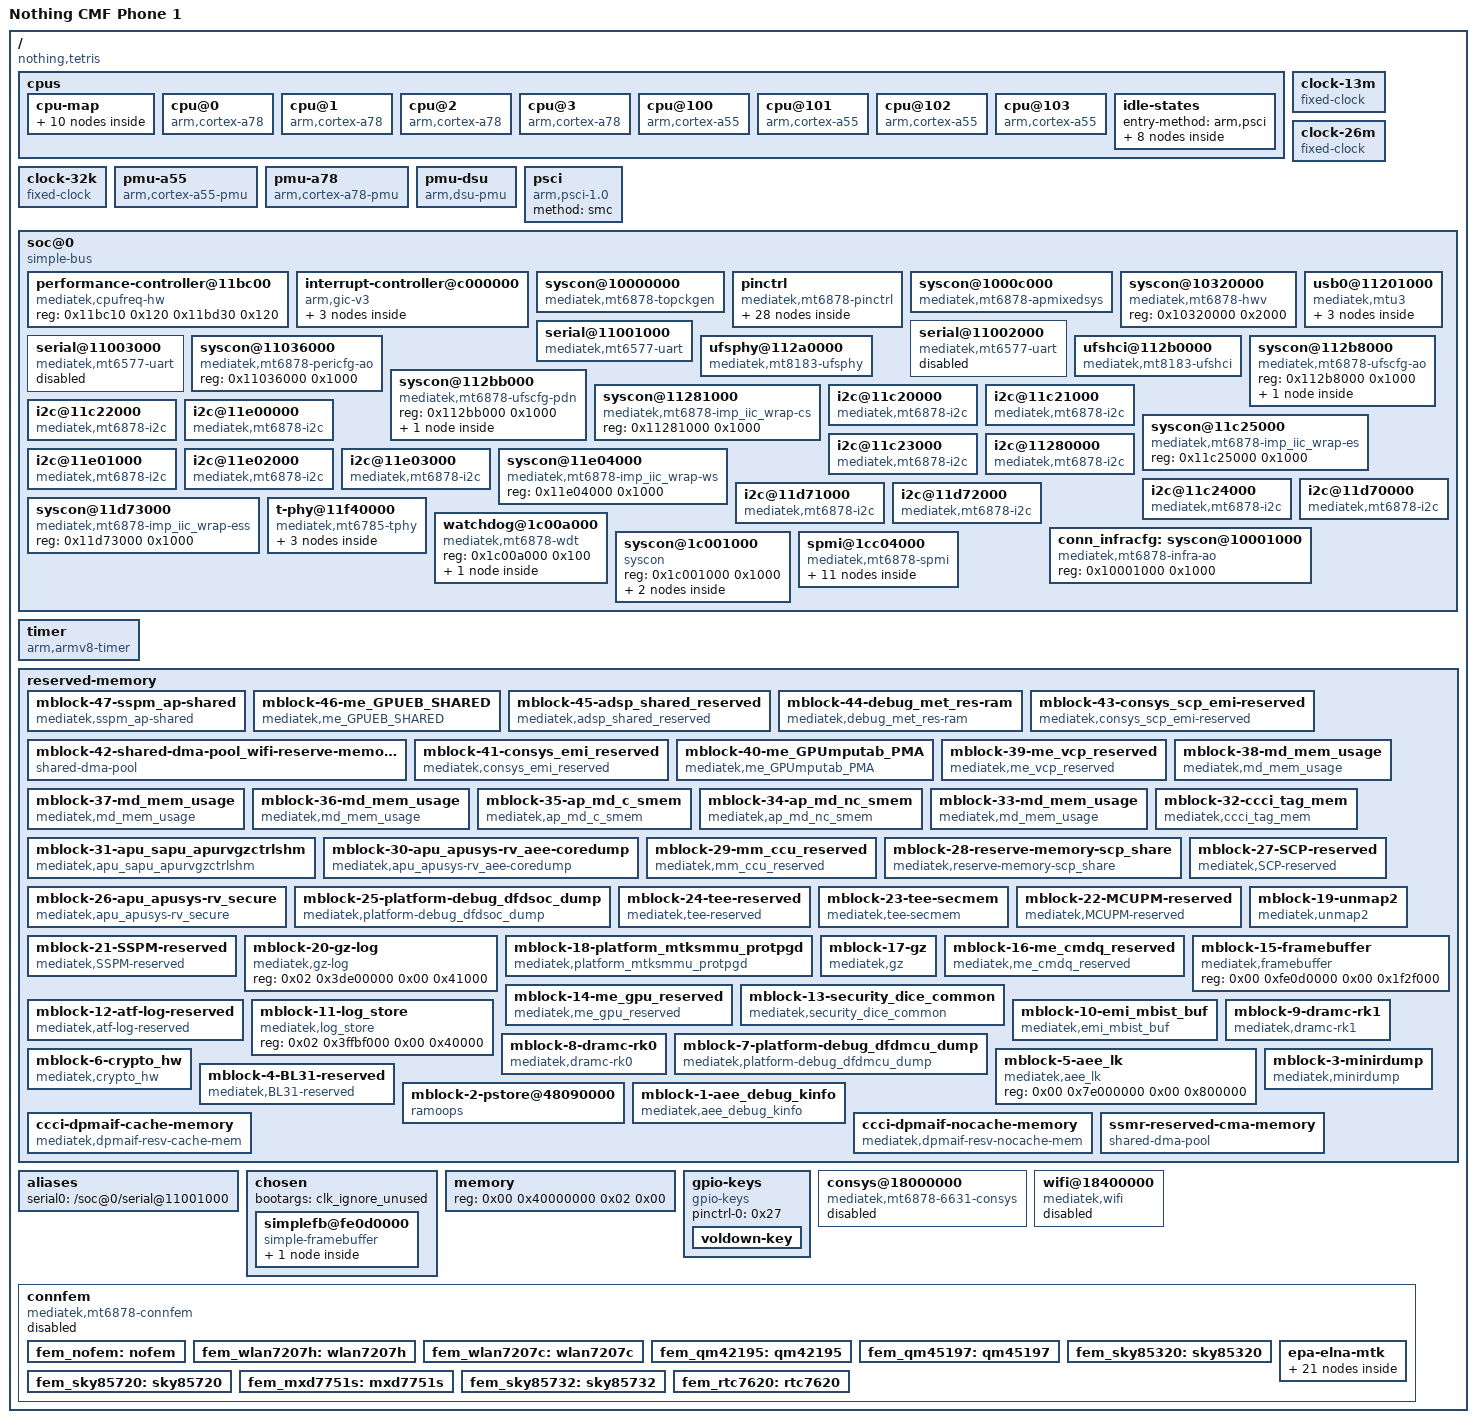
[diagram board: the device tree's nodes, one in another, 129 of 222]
/dts-v1/;

/ {
	compatible = "nothing,tetris", "mediatek,mt6878";
	#address-cells = <0x02>;
	#size-cells = <0x02>;
	interrupt-parent = <0x01>;
	model = "Nothing CMF Phone 1";
	chassis-type = "handset";

	cpus {
		#address-cells = <0x01>;
		#size-cells = <0x00>;

		cpu-map {

			cluster0 {

				core0 {
					cpu = <0x02>;
				};

				core1 {
					cpu = <0x03>;
				};

				core2 {
					cpu = <0x04>;
				};

				core3 {
					cpu = <0x05>;
				};
			};

			cluster1 {

				core0 {
					cpu = <0x06>;
				};

				core1 {
					cpu = <0x07>;
				};

				core2 {
					cpu = <0x08>;
				};

				core3 {
					cpu = <0x09>;
				};
			};
		};

		cpu@0 {
			device_type = "cpu";
			compatible = "arm,cortex-a78";
			reg = <0x00>;
			performance-domains = <0x0a 0x00>;
			enable-method = "psci";
			cpu-idle-states = <0x0b 0x0c 0x0d 0x0e 0x0f>;
			capacity-dmips-mhz = <0x10b>;
			phandle = <0x02>;
		};

		cpu@1 {
			device_type = "cpu";
			compatible = "arm,cortex-a78";
			reg = <0x100>;
			performance-domains = <0x0a 0x00>;
			enable-method = "psci";
			cpu-idle-states = <0x0b 0x0c 0x0d 0x0e 0x0f>;
			capacity-dmips-mhz = <0x10b>;
			phandle = <0x03>;
		};

		cpu@2 {
			device_type = "cpu";
			compatible = "arm,cortex-a78";
			reg = <0x200>;
			performance-domains = <0x0a 0x00>;
			enable-method = "psci";
			cpu-idle-states = <0x0b 0x0c 0x0d 0x0e 0x0f>;
			capacity-dmips-mhz = <0x10b>;
			phandle = <0x04>;
		};

		cpu@3 {
			device_type = "cpu";
			compatible = "arm,cortex-a78";
			reg = <0x300>;
			performance-domains = <0x0a 0x00>;
			enable-method = "psci";
			cpu-idle-states = <0x0b 0x0c 0x0d 0x0e 0x0f>;
			capacity-dmips-mhz = <0x10b>;
			phandle = <0x05>;
		};

		cpu@100 {
			device_type = "cpu";
			compatible = "arm,cortex-a55";
			reg = <0x400>;
			performance-domains = <0x0a 0x01>;
			enable-method = "psci";
			cpu-idle-states = <0x10 0x11 0x12 0x0e 0x0f>;
			capacity-dmips-mhz = <0x400>;
			phandle = <0x06>;
		};

		cpu@101 {
			device_type = "cpu";
			compatible = "arm,cortex-a55";
			reg = <0x500>;
			performance-domains = <0x0a 0x01>;
			enable-method = "psci";
			cpu-idle-states = <0x10 0x11 0x12 0x0e 0x0f>;
			capacity-dmips-mhz = <0x400>;
			phandle = <0x07>;
		};

		cpu@102 {
			device_type = "cpu";
			compatible = "arm,cortex-a55";
			reg = <0x600>;
			performance-domains = <0x0a 0x01>;
			enable-method = "psci";
			cpu-idle-states = <0x10 0x11 0x12 0x0e 0x0f>;
			capacity-dmips-mhz = <0x400>;
			phandle = <0x08>;
		};

		cpu@103 {
			device_type = "cpu";
			compatible = "arm,cortex-a55";
			reg = <0x700>;
			performance-domains = <0x0a 0x01>;
			enable-method = "psci";
			cpu-idle-states = <0x10 0x11 0x12 0x0e 0x0f>;
			capacity-dmips-mhz = <0x400>;
			phandle = <0x09>;
		};

		idle-states {
			entry-method = "arm,psci";

			cpuoff-l {
				compatible = "arm,idle-state";
				arm,psci-suspend-param = <0x10000>;
				local-timer-stop;
				entry-latency-us = <0x19>;
				exit-latency-us = <0x39>;
				min-residency-us = <0x1644>;
				phandle = <0x0b>;
			};

			cpuoff-b {
				compatible = "arm,idle-state";
				arm,psci-suspend-param = <0x10000>;
				local-timer-stop;
				entry-latency-us = <0x23>;
				exit-latency-us = <0x52>;
				min-residency-us = <0x762>;
				phandle = <0x10>;
			};

			clusteroff-l {
				compatible = "arm,idle-state";
				arm,psci-suspend-param = <0x1010001>;
				local-timer-stop;
				entry-latency-us = <0x39>;
				exit-latency-us = <0x86>;
				min-residency-us = <0x1644>;
				phandle = <0x0c>;
			};

			clusteroff-b {
				compatible = "arm,idle-state";
				arm,psci-suspend-param = <0x1010001>;
				local-timer-stop;
				entry-latency-us = <0x32>;
				exit-latency-us = <0x90>;
				min-residency-us = <0x99c>;
				phandle = <0x11>;
			};

			mcusysoff-l {
				compatible = "arm,idle-state";
				arm,psci-suspend-param = <0x2010007>;
				local-timer-stop;
				entry-latency-us = <0x35f>;
				exit-latency-us = <0x4d5>;
				min-residency-us = <0x1644>;
				phandle = <0x0d>;
			};

			mcusysoff-b {
				compatible = "arm,idle-state";
				arm,psci-suspend-param = <0x2010007>;
				local-timer-stop;
				entry-latency-us = <0x288>;
				exit-latency-us = <0x494>;
				min-residency-us = <0x11da>;
				phandle = <0x12>;
			};

			system-vcore {
				compatible = "arm,idle-state";
				arm,psci-suspend-param = <0x20100ff>;
				local-timer-stop;
				entry-latency-us = <0x960>;
				exit-latency-us = <0x12c0>;
				min-residency-us = <0x8980>;
				phandle = <0x0e>;
			};

			s2idle {
				compatible = "arm,idle-state";
				arm,psci-suspend-param = <0x20180ff>;
				local-timer-stop;
				entry-latency-us = <0x2710>;
				exit-latency-us = <0x2710>;
				min-residency-us = <0xffffffff>;
				phandle = <0x0f>;
			};
		};
	};

	clock-13m {
		compatible = "fixed-clock";
		#clock-cells = <0x00>;
		clock-frequency = <0xc65d40>;
		clock-output-names = "clk13m";
	};

	clock-26m {
		compatible = "fixed-clock";
		#clock-cells = <0x00>;
		clock-frequency = <0x18cba80>;
		clock-output-names = "clk26m";
		phandle = <0x17>;
	};

	clock-32k {
		compatible = "fixed-clock";
		#clock-cells = <0x00>;
		clock-frequency = <0x7d00>;
		clock-output-names = "clk32k";
	};

	pmu-a55 {
		compatible = "arm,cortex-a55-pmu";
		interrupt-parent = <0x01>;
		interrupts = <0x01 0x07 0x04 0x13>;
	};

	pmu-a78 {
		compatible = "arm,cortex-a78-pmu";
		interrupt-parent = <0x01>;
		interrupts = <0x01 0x07 0x04 0x14>;
	};

	pmu-dsu {
		compatible = "arm,dsu-pmu";
		cpus = <0x02 0x03 0x04 0x05 0x06 0x07 0x08 0x09>;
		interrupts = <0x00 0x23 0x04 0x00>;
	};

	psci {
		compatible = "arm,psci-1.0";
		method = "smc";
	};

	soc@0 {
		compatible = "simple-bus";
		ranges = <0x00 0x00 0x00 0x20000000>;
		#address-cells = <0x01>;
		#size-cells = <0x01>;

		performance-controller@11bc00 {
			compatible = "mediatek,cpufreq-hw";
			reg = <0x11bc10 0x120 0x11bd30 0x120>;
			#performance-domain-cells = <0x01>;
			phandle = <0x0a>;
		};

		interrupt-controller@c000000 {
			compatible = "arm,gic-v3";
			reg = <0xc000000 0x40000 0xc040000 0x200000>;
			#interrupt-cells = <0x04>;
			interrupt-controller;
			interrupts = <0x01 0x09 0x04 0x00>;
			phandle = <0x01>;

			ppi-partitions {

				interrupt-partition-0 {
					affinity = <0x02 0x03 0x04 0x05>;
					phandle = <0x13>;
				};

				interrupt-partition-1 {
					affinity = <0x06 0x07 0x08 0x09>;
					phandle = <0x14>;
				};
			};
		};

		syscon@10000000 {
			compatible = "mediatek,mt6878-topckgen", "syscon";
			reg = <0x10000000 0x1000>;
			#clock-cells = <0x01>;
			hw-voter-regmap = <0x15>;
			phandle = <0x1a>;
		};

		pinctrl {
			compatible = "mediatek,mt6878-pinctrl";
			reg = <0x10005000 0x1000 0x11d10000 0x1000 0x11d30000 0x1000 0x11d40000 0x1000 0x11d50000 0x1000 0x11d60000 0x1000 0x11e20000 0x1000 0x11e30000 0x1000 0x11eb0000 0x1000 0x11ec0000 0x1000 0x11ce0000 0x1000 0x11de0000 0x1000 0x11e60000 0x1000 0x1c01e000 0x1000 0x11ce0000 0x1000 0x11de0000 0x1000 0x11e60000 0x1000 0x1c01e000 0x1000>;
			reg-names = "gpio", "iocfg_bl", "iocfg_bm", "iocfg_br", "iocfg_bl1", "iocfg_br1", "iocfg_lm", "iocfg_lt", "iocfg_rm", "iocfg_rt", "eint-e", "eint-s", "eint-w", "eint-c";
			gpio-controller;
			#gpio-cells = <0x02>;
			gpio-ranges = <0x16 0x00 0x00 0xc4>;
			interrupt-controller;
			#interrupt-cells = <0x02>;
			interrupts = <0x00 0xef 0x04 0x00>;
			phandle = <0x16>;

			key-default {
				phandle = <0x27>;

				pins-cmd1-dat {
					pinmux = <0x3600>;
					input-enable;
					bias-pull-up;
				};
			};
		};

		syscon@1000c000 {
			compatible = "mediatek,mt6878-apmixedsys", "syscon";
			reg = <0x1000c000 0x1000>;
			#clock-cells = <0x01>;
			mediatek,hardware-voter = <0x15>;
		};

		syscon@10320000 {
			compatible = "mediatek,mt6878-hwv", "syscon";
			reg = <0x10320000 0x2000>;
			phandle = <0x15>;
		};

		serial@11001000 {
			compatible = "mediatek,mt6577-uart";
			reg = <0x11001000 0x1000>;
			interrupts = <0x00 0x18d 0x04 0x00>;
			clocks = <0x17 0x18 0x00>;
			clock-names = "baud", "bus";
			status = "okay";
		};

		serial@11002000 {
			compatible = "mediatek,mt6577-uart";
			reg = <0x11002000 0x1000>;
			interrupts = <0x00 0x18e 0x04 0x00>;
			clocks = <0x17 0x18 0x01>;
			clock-names = "baud", "bus";
			status = "disabled";
		};

		serial@11003000 {
			compatible = "mediatek,mt6577-uart";
			reg = <0x11003000 0x1000>;
			interrupts = <0x00 0x18f 0x04 0x00>;
			clocks = <0x17 0x18 0x02>;
			clock-names = "baud", "bus";
			status = "disabled";
		};

		syscon@11036000 {
			compatible = "mediatek,mt6878-pericfg-ao", "syscon";
			reg = <0x11036000 0x1000>;
			#clock-cells = <0x01>;
			phandle = <0x18>;
		};

		usb0@11201000 {
			dr_mode = "peripheral";
			compatible = "mediatek,mtu3";
			reg = <0x11201000 0x2e00 0x11203e00 0x100>;
			reg-names = "mac", "ippc";
			interrupts = <0x00 0x180 0x04 0x00>;
			phy-cells = <0x01>;
			phys = <0x19 0x03>;
			clocks = <0x1a 0x1f 0x1a 0x20 0x18 0x12>;
			clock-names = "sys_ck", "host_ck", "frmcnt_ck";
			#address-cells = <0x01>;
			#size-cells = <0x01>;
			ranges;
			mediatek,syscon-wakeup = <0x18 0x214 0x69>;
			wakeup-source;

			xhci0@11200000 {
				compatible = "mediatek,mtk-xhci";
				reg = <0x11200000 0x1000>;
				reg-names = "mac";
				interrupts = <0x00 0x181 0x04 0x00>;
				clocks = <0x17>;
				clock-names = "sys_ck";

				port {

					endpoint {
						remote-endpoint = <0x1b>;
						phandle = <0x25>;
					};
				};
			};
		};

		ufsphy@112a0000 {
			compatible = "mediatek,mt8183-ufsphy";
			#phy-cells = <0x00>;
			clocks = <0x17 0x17>;
			clock-names = "unipro", "mp";
			reg = <0x112a0000 0x10000>;
			status = "okay";
			phandle = <0x1c>;
		};

		ufshci@112b0000 {
			compatible = "mediatek,mt8183-ufshci";
			reg = <0x112b0000 0x2300>;
			phys = <0x1c>;
			interrupts = <0x00 0x189 0x04 0x00>;
			clocks = <0x1a 0x29 0x1a 0x28 0x1a 0x2a 0x1d 0x00 0x1d 0x01 0x1d 0x02 0x1d 0x03 0x1d 0x04 0x1d 0x05 0x1e 0x00 0x1e 0x01 0x1e 0x02 0x1e 0x03>;
			clock-names = "ufs_sel", "ufs_fde", "ufs_mbist", "unipro_tx_sym", "unipro_rx_sym0", "unipro_rx_sym1", "unipro_sys", "unipro_phy_sap", "phy_top_ahb_s_bus", "ufshci_ufs", "ufshci_aes", "ufshci_ufs_ahb", "ufshci_aes_axi";
			freq-table-hz = <0x00 0x00 0x00 0x00 0x00 0x00 0x00 0x00 0x00 0x00 0x00 0x00 0x00 0x00 0x00 0x00 0x00 0x00 0x00 0x00 0x00 0x00 0x00 0x00 0x00 0x00>;
			resets = <0x1f 0x00 0x1f 0x01 0x1f 0x02>;
			reset-names = "unipro_rst", "crypto_rst", "hci_rst";
			mediatek,ufs-disable-mcq;
			status = "okay";
		};

		syscon@112b8000 {
			compatible = "mediatek,mt6878-ufscfg-ao", "syscon", "simple-mfd";
			reg = <0x112b8000 0x1000>;
			#clock-cells = <0x01>;
			phandle = <0x1d>;

			reset-controller {
				compatible = "ti,syscon-reset";
				#reset-cells = <0x01>;
				ti,reset-bits = <0x48 0x08 0x4c 0x08 0x00 0x00 0x1c>;
			};
		};

		syscon@112bb000 {
			compatible = "mediatek,mt6878-ufscfg-pdn", "syscon", "simple-mfd";
			reg = <0x112bb000 0x1000>;
			#clock-cells = <0x01>;
			phandle = <0x1e>;

			reset-controller {
				compatible = "ti,syscon-reset";
				#reset-cells = <0x01>;
				ti,reset-bits = <0x48 0x00 0x4c 0x00 0x00 0x00 0x1c 0x48 0x01 0x4c 0x01 0x00 0x00 0x1c 0x48 0x02 0x4c 0x02 0x00 0x00 0x1c>;
				phandle = <0x1f>;
			};
		};

		syscon@11281000 {
			compatible = "mediatek,mt6878-imp_iic_wrap-cs", "syscon";
			reg = <0x11281000 0x1000>;
			#clock-cells = <0x01>;
			phandle = <0x23>;
		};

		i2c@11c20000 {
			compatible = "mediatek,mt6878-i2c", "mediatek,mt8188-i2c";
			reg = <0x11c20000 0x1000 0x11300200 0x80>;
			interrupts = <0x00 0x190 0x04 0x00>;
			clocks = <0x21 0x00 0x18 0x11>;
			clock-names = "main", "dma";
			clock-div = <0x01>;
		};

		i2c@11c21000 {
			compatible = "mediatek,mt6878-i2c", "mediatek,mt8188-i2c";
			reg = <0x11c21000 0x1000 0x11300280 0x80>;
			interrupts = <0x00 0x191 0x04 0x00>;
			clocks = <0x21 0x01 0x18 0x11>;
			clock-names = "main", "dma";
			clock-div = <0x01>;
		};

		i2c@11c22000 {
			compatible = "mediatek,mt6878-i2c", "mediatek,mt8188-i2c";
			reg = <0x11c22000 0x1000 0x11300300 0x100>;
			interrupts = <0x00 0x192 0x04 0x00>;
			clocks = <0x21 0x02 0x18 0x11>;
			clock-names = "main", "dma";
			clock-div = <0x01>;
		};

		syscon@11c25000 {
			compatible = "mediatek,mt6878-imp_iic_wrap-es", "syscon";
			reg = <0x11c25000 0x1000>;
			#clock-cells = <0x01>;
			phandle = <0x21>;
		};

		i2c@11e00000 {
			compatible = "mediatek,mt6878-i2c", "mediatek,mt8188-i2c";
			reg = <0x11e00000 0x1000 0x11300400 0x80>;
			interrupts = <0x00 0x193 0x04 0x00>;
			clocks = <0x22 0x00 0x18 0x11>;
			clock-names = "main", "dma";
			clock-div = <0x01>;
		};

		i2c@11c23000 {
			compatible = "mediatek,mt6878-i2c", "mediatek,mt8188-i2c";
			reg = <0x11c23000 0x1000 0x11300480 0x100>;
			interrupts = <0x00 0x194 0x04 0x00>;
			clocks = <0x21 0x03 0x18 0x11>;
			clock-names = "main", "dma";
			clock-div = <0x01>;
		};

		i2c@11280000 {
			compatible = "mediatek,mt6878-i2c", "mediatek,mt8188-i2c";
			#address-cells = <0x01>;
			#size-cells = <0x00>;
			reg = <0x11280000 0x1000 0x11300580 0x80>;
			interrupts = <0x00 0x195 0x04 0x00>;
			clocks = <0x23 0x00 0x18 0x11>;
			clock-names = "main", "dma";
			clock-div = <0x01>;
		};

		i2c@11e01000 {
			compatible = "mediatek,mt6878-i2c", "mediatek,mt8188-i2c";
			#address-cells = <0x01>;
			#size-cells = <0x00>;
			reg = <0x11e01000 0x1000 0x11300600 0x80>;
			interrupts = <0x00 0x196 0x04 0x00>;
			clocks = <0x22 0x01 0x18 0x11>;
			clock-names = "main", "dma";
			clock-div = <0x01>;
		};

		i2c@11e02000 {
			compatible = "mediatek,mt6878-i2c", "mediatek,mt8188-i2c";
			reg = <0x11e02000 0x1000 0x11300680 0x100>;
			interrupts = <0x00 0x197 0x04 0x00>;
			clocks = <0x22 0x02 0x18 0x11>;
			clock-names = "main", "dma";
			clock-div = <0x01>;
			scl-gpio-id = <0x8b>;
			sda-gpio-id = <0x8c>;
		};

		i2c@11e03000 {
			compatible = "mediatek,mt6878-i2c", "mediatek,mt8188-i2c";
			reg = <0x11e03000 0x1000 0x11300780 0x100>;
			interrupts = <0x00 0x198 0x04 0x00>;
			clocks = <0x22 0x03 0x18 0x11>;
			clock-names = "main", "dma";
			clock-div = <0x01>;
		};

		syscon@11e04000 {
			compatible = "mediatek,mt6878-imp_iic_wrap-ws", "syscon";
			reg = <0x11e04000 0x1000>;
			#clock-cells = <0x01>;
			phandle = <0x22>;
		};

		i2c@11c24000 {
			compatible = "mediatek,mt6878-i2c", "mediatek,mt8188-i2c";
			reg = <0x11c24000 0x1000 0x11300880 0x100>;
			interrupts = <0x00 0x199 0x04 0x00>;
			clocks = <0x21 0x04 0x18 0x11>;
			clock-names = "main", "dma";
			clock-div = <0x01>;
		};

		i2c@11d70000 {
			compatible = "mediatek,mt6878-i2c", "mediatek,mt8188-i2c";
			reg = <0x11d70000 0x1000 0x11300980 0x80>;
			interrupts = <0x00 0x19a 0x04 0x00>;
			clocks = <0x24 0x00 0x18 0x11>;
			clock-names = "main", "dma";
			clock-div = <0x01>;
		};

		i2c@11d71000 {
			compatible = "mediatek,mt6878-i2c", "mediatek,mt8188-i2c";
			reg = <0x11d71000 0x1000 0x11300a00 0x80>;
			interrupts = <0x00 0x19b 0x04 0x00>;
			clocks = <0x24 0x01 0x18 0x11>;
			clock-names = "main", "dma";
			clock-div = <0x01>;
		};

		i2c@11d72000 {
			compatible = "mediatek,mt6878-i2c", "mediatek,mt8188-i2c";
			reg = <0x11d72000 0x1000 0x11300a80 0x80>;
			interrupts = <0x00 0x19c 0x04 0x00>;
			clocks = <0x24 0x02 0x18 0x11>;
			clock-names = "main", "dma";
			clock-div = <0x01>;
		};

		syscon@11d73000 {
			compatible = "mediatek,mt6878-imp_iic_wrap-ess", "syscon";
			reg = <0x11d73000 0x1000>;
			#clock-cells = <0x01>;
			phandle = <0x24>;
		};

		t-phy@11f40000 {
			compatible = "mediatek,mt6785-tphy", "mediatek,generic-tphy-v2";
			#address-cells = <0x01>;
			#size-cells = <0x01>;
			ranges = <0x00 0x11f40000 0x1000>;
			status = "okay";

			usb-phy@0 {
				reg = <0x00 0x700>;
				clocks = <0x17>;
				clock-names = "ref";
				#phy-cells = <0x01>;
				mediatek,software-role-switch;
				status = "okay";
				phandle = <0x19>;

				port {

					endpoint {
						remote-endpoint = <0x25>;
						phandle = <0x1b>;
					};
				};
			};
		};

		watchdog@1c00a000 {
			compatible = "mediatek,mt6878-wdt", "mediatek,mt6589-wdt", "syscon";
			reg = <0x1c00a000 0x100>;

			reboot-mode {
				compatible = "syscon-reboot-mode";
				offset = <0x24>;
				mask = <0x0f>;
				mode-charger = <0x01>;
				mode-recovery = <0x02>;
				mode-bootloader = <0x03>;
				mode-dm-verity-dev-corrupt = <0x04>;
				mode-kpoc = <0x05>;
				mode-ddr-reserve = <0x06>;
				mode-meta = <0x07>;
				mode-rpmbpk = <0x08>;
			};
		};
	};

	timer {
		compatible = "arm,armv8-timer";
		interrupt-parent = <0x01>;
		interrupts = <0x01 0x0d 0x08 0x00 0x01 0x0e 0x08 0x00 0x01 0x0b 0x08 0x00 0x01 0x0a 0x08 0x00>;
	};

	reserved-memory {
		#address-cells = <0x02>;
		#size-cells = <0x02>;
		ranges;

		mblock-47-sspm_ap-shared {
			reg = <0x00 0x7f970000 0x00 0x110000>;
			no-map;
			compatible = "mediatek,sspm_ap-shared";
		};

		mblock-46-me_GPUEB_SHARED {
			reg = <0x00 0x7fe70000 0x00 0x180000>;
			no-map;
			compatible = "mediatek,me_GPUEB_SHARED";
		};

		mblock-45-adsp_shared_reserved {
			reg = <0x00 0x9e000000 0x00 0xb70000>;
			no-map;
			compatible = "mediatek,adsp_shared_reserved";
		};

		mblock-44-debug_met_res-ram {
			reg = <0x00 0x9f3ff000 0x00 0xc00000>;
			no-map;
			compatible = "mediatek,debug_met_res-ram";
		};

		mblock-43-consys_scp_emi-reserved {
			reg = <0x00 0x87f00000 0x00 0x20000>;
			no-map;
			compatible = "mediatek,consys_scp_emi-reserved";
		};

		mblock-42-shared-dma-pool_wifi-reserve-memory_dma {
			phandle = <0x312>;
			reg = <0x00 0x86b00000 0x00 0x1400000>;
			no-map;
			compatible = "shared-dma-pool";
		};

		mblock-41-consys_emi_reserved {
			reg = <0x00 0x85e00000 0x00 0xd00000>;
			no-map;
			compatible = "mediatek,consys_emi_reserved";
		};

		mblock-40-me_GPUmputab_PMA {
			reg = <0x00 0x7e800000 0x00 0x600000>;
			no-map;
			compatible = "mediatek,me_GPUmputab_PMA";
		};

		mblock-39-me_vcp_reserved {
			reg = <0x00 0xbf500000 0x00 0x800000>;
			no-map;
			compatible = "mediatek,me_vcp_reserved";
		};

		mblock-38-md_mem_usage {
			reg = <0x00 0xed780000 0x00 0x880000>;
			no-map;
			compatible = "mediatek,md_mem_usage";
		};

		mblock-37-md_mem_usage {
			reg = <0x00 0xd4000000 0x00 0x6fa0000>;
			no-map;
			compatible = "mediatek,md_mem_usage";
		};

		mblock-36-md_mem_usage {
			reg = <0x00 0xd3500000 0x00 0x250000>;
			no-map;
			compatible = "mediatek,md_mem_usage";
		};

		mblock-35-ap_md_c_smem {
			reg = <0x00 0x88000000 0x00 0x2560000>;
			no-map;
			compatible = "mediatek,ap_md_c_smem";
		};

		mblock-34-ap_md_nc_smem {
			reg = <0x00 0x8c000000 0x00 0x130000>;
			no-map;
			compatible = "mediatek,ap_md_nc_smem";
		};

		mblock-33-md_mem_usage {
			reg = <0x00 0xd0000000 0x00 0x34e0000>;
			no-map;
			compatible = "mediatek,md_mem_usage";
		};

		mblock-32-ccci_tag_mem {
			reg = <0x00 0xbfdf0000 0x00 0x10000>;
			no-map;
			compatible = "mediatek,ccci_tag_mem";
		};

		mblock-31-apu_sapu_apurvgzctrlshm {
			reg = <0x00 0x8f600000 0x00 0x100000>;
			no-map;
			compatible = "mediatek,apu_sapu_apurvgzctrlshm";
		};

		mblock-30-apu_apusys-rv_aee-coredump {
			reg = <0x00 0x8f7a0000 0x00 0x260000>;
			no-map;
			compatible = "mediatek,apu_apusys-rv_aee-coredump";
		};

		mblock-29-mm_ccu_reserved {
			reg = <0x00 0x80000000 0x00 0x100000>;
			no-map;
			compatible = "mediatek,mm_ccu_reserved";
		};

		mblock-28-reserve-memory-scp_share {
			reg = <0x00 0x8e000000 0x00 0x11c8000>;
			no-map;
			compatible = "mediatek,reserve-memory-scp_share";
		};

		mblock-27-SCP-reserved {
			reg = <0x00 0xb8000000 0x00 0x2300000>;
			no-map;
			compatible = "mediatek,SCP-reserved";
		};

		mblock-26-apu_apusys-rv_secure {
			reg = <0x00 0x8fa00000 0x00 0x600000>;
			no-map;
			compatible = "mediatek,apu_apusys-rv_secure";
		};

		mblock-25-platform-debug_dfdsoc_dump {
			reg = <0x00 0xf9c00000 0x00 0x200000>;
			no-map;
			compatible = "mediatek,platform-debug_dfdsoc_dump";
		};

		mblock-24-tee-reserved {
			reg = <0x00 0x70000000 0x00 0x6c00000>;
			no-map;
			compatible = "mediatek,tee-reserved";
		};

		mblock-23-tee-secmem {
			reg = <0x00 0x7f000000 0x00 0x900000>;
			no-map;
			compatible = "mediatek,tee-secmem";
		};

		mblock-22-MCUPM-reserved {
			reg = <0x00 0x7fa80000 0x00 0x100000>;
			no-map;
			compatible = "mediatek,MCUPM-reserved";
		};

		mblock-21-SSPM-reserved {
			reg = <0x00 0x7fb80000 0x00 0x280000>;
			no-map;
			compatible = "mediatek,SSPM-reserved";
		};

		mblock-20-gz-log {
			reg = <0x02 0x3de00000 0x00 0x41000>;
			compatible = "mediatek,gz-log";
		};

		mblock-19-unmap2 {
			reg = <0x02 0x3e000000 0x00 0x200000>;
			no-map;
			compatible = "mediatek,unmap2";
		};

		mblock-18-platform_mtksmmu_protpgd {
			reg = <0x00 0xf9e00000 0x00 0x4200000>;
			no-map;
			compatible = "mediatek,platform_mtksmmu_protpgd";
		};

		mblock-17-gz {
			reg = <0x02 0x3e400000 0x00 0x1a00000>;
			no-map;
			compatible = "mediatek,gz";
		};

		mblock-16-me_cmdq_reserved {
			reg = <0x02 0x3fe00000 0x00 0x100000>;
			no-map;
			compatible = "mediatek,me_cmdq_reserved";
		};

		mblock-15-framebuffer {
			reg = <0x00 0xfe0d0000 0x00 0x1f2f000>;
			compatible = "mediatek,framebuffer";
		};

		mblock-14-me_gpu_reserved {
			reg = <0x00 0x7ee00000 0x00 0x200000>;
			no-map;
			compatible = "mediatek,me_gpu_reserved";
		};

		mblock-13-security_dice_common {
			reg = <0x00 0x6fffe000 0x00 0x1000>;
			no-map;
			compatible = "mediatek,security_dice_common";
		};

		mblock-12-atf-log-reserved {
			reg = <0x00 0xbfe00000 0x00 0x200000>;
			no-map;
			compatible = "mediatek,atf-log-reserved";
		};

		mblock-11-log_store {
			reg = <0x02 0x3ffbf000 0x00 0x40000>;
			compatible = "mediatek,log_store";
		};

		mblock-10-emi_mbist_buf {
			reg = <0x00 0x7ffff000 0x00 0x1000>;
			no-map;
			compatible = "mediatek,emi_mbist_buf";
		};

		mblock-9-dramc-rk1 {
			reg = <0x02 0x3ffff000 0x00 0x1000>;
			no-map;
			compatible = "mediatek,dramc-rk1";
		};

		mblock-8-dramc-rk0 {
			reg = <0x01 0x3ffff000 0x00 0x1000>;
			no-map;
			compatible = "mediatek,dramc-rk0";
		};

		mblock-7-platform-debug_dfdmcu_dump {
			reg = <0x00 0xf9000000 0x00 0x100000>;
			no-map;
			compatible = "mediatek,platform-debug_dfdmcu_dump";
		};

		mblock-6-crypto_hw {
			reg = <0x00 0x48401000 0x00 0x1000>;
			no-map;
			compatible = "mediatek,crypto_hw";
		};

		mblock-5-aee_lk {
			reg = <0x00 0x7e000000 0x00 0x800000>;
			compatible = "mediatek,aee_lk";
		};

		mblock-4-BL31-reserved {
			reg = <0x00 0x48800000 0x00 0x200000>;
			no-map;
			compatible = "mediatek,BL31-reserved";
		};

		mblock-3-minirdump {
			reg = <0x00 0x48170000 0x00 0x10000>;
			no-map;
			compatible = "mediatek,minirdump";
		};

		mblock-2-pstore@48090000 {
			compatible = "ramoops";
			reg = <0x00 0x48090000 0x00 0xe0000>;
			no-map;
			record-size = <0x1000>;
			console-size = <0x40000>;
			pmsg-size = <0x80000>;
			ftrace-size = <0x1000>;
			flags = <0x01>;
			ecc-size = <0x00>;
			mem-type = <0x00>;
			max-reason = <0x02>;
		};

		mblock-1-aee_debug_kinfo {
			phandle = <0x311>;
			reg = <0x00 0x48080000 0x00 0x10000>;
			no-map;
			compatible = "mediatek,aee_debug_kinfo";
		};

		ccci-dpmaif-cache-memory {
			compatible = "mediatek,dpmaif-resv-cache-mem";
			size = <0x00 0x190000>;
			alignment = <0x00 0x1000>;
			alloc-ranges = <0x00 0x40000000 0x00 0xf0000000>;
			phandle = <0x14b>;
		};

		ccci-dpmaif-nocache-memory {
			compatible = "mediatek,dpmaif-resv-nocache-mem";
			no-map;
			size = <0x00 0x50000>;
			alignment = <0x00 0x1000>;
			alloc-ranges = <0x00 0x40000000 0x00 0xf0000000>;
			phandle = <0x14c>;
		};

		ssmr-reserved-cma-memory {
			alloc-ranges = <0x00 0x80000000 0x00 0xc0000000>;
			compatible = "shared-dma-pool";
			reusable;
			size = <0x00 0xd000000>;
			alignment = <0x00 0x1000000>;
			phandle = <0x20>;
		};
	};

	aliases {
		serial0 = "/soc@0/serial@11001000";
	};

	chosen {
		bootargs = "clk_ignore_unused";
		#address-cells = <0x02>;
		#size-cells = <0x02>;
		ranges;

		simplefb@fe0d0000 {
			compatible = "simple-framebuffer";
			reg = <0x00 0xfe0d0000 0x00 0xa08c00>;
			width = <0x438>;
			height = <0x960>;
			stride = <0x1100>;
			format = "a8r8g8b8";
			panel = <0x26>;

			fb-panel {
				width-mm = <0x4b>;
				height-mm = <0xa0>;
				phandle = <0x26>;
			};
		};
	};

	memory {
		device_type = "memory";
		reg = <0x00 0x40000000 0x02 0x00>;
	};

	gpio-keys {
		compatible = "gpio-keys";
		pinctrl-0 = <0x27>;
		pinctrl-names = "default";

		voldown-key {
			label = "Volume Down";
			linux,code = <0x72>;
			gpios = <0x16 0x36 0x01>;
		};
	};
};
/* SPDX-License-Identifier: (GPL-2.0-only OR BSD-2-Clause) */
/* Apply after the v9 board tree. The radio consumers are staged disabled. */

&{/soc@0} {
	conn_infracfg: syscon@10001000 {
		compatible = "mediatek,mt6878-infra-ao", "syscon";
		reg = <0x10001000 0x1000>;
	};

	syscon@1c001000 {
		compatible = "syscon", "simple-mfd";
		reg = <0x1c001000 0x1000>;

		conn_power: power-controller {
			compatible = "mediatek,mt6878-power-controller";
			access-controllers = <&conn_infracfg>;
			#address-cells = <1>;
			#size-cells = <0>;
			#power-domain-cells = <1>;

			power-domain@1 {
				reg = <1>;
				#power-domain-cells = <0>;
			};
		};
	};

	spmi@1cc04000 {
		compatible = "mediatek,mt6878-spmi";
		reg = <0x1cc04000 0x8ff>, <0x1cc01000 0x100>;
		reg-names = "pmif", "spmimst";
		interrupts-extended = <&{/soc@0/pinctrl} 212 4>;
		interrupt-names = "rcs";
		interrupt-controller;
		#interrupt-cells = <3>;
		#address-cells = <2>;
		#size-cells = <0>;

		pmic@4 {
			compatible = "mediatek,mt6363-rf-regulators";
			reg = <4 0>;

			conninfra {
				compatible = "mediatek,mt6363-consys";
			};

			regulators {
				mt6363_vcn13: vcn13 {
					regulator-name = "mt6363_vcn13";
					regulator-min-microvolt = <900000>;
					regulator-max-microvolt = <1810000>;
					regulator-enable-ramp-delay = <180>;
					regulator-allowed-modes = <0 2>;
				};

				mt6363_vrfio18: vrfio18 {
					regulator-name = "mt6363_vrfio18";
					regulator-min-microvolt = <600000>;
					regulator-max-microvolt = <2100000>;
					regulator-enable-ramp-delay = <180>;
					regulator-allowed-modes = <0 2>;
				};
			};
		};

		pmic@5 {
			compatible = "mediatek,mt6369-rf-regulators";
			reg = <5 0>;

			conninfra {
				compatible = "mediatek,mt6369-consys";
			};

			regulators {
				mt6369_vcn33_1: vcn33-1 {
					regulator-name = "mt6369_vcn33_1";
					regulator-min-microvolt = <1200000>;
					regulator-max-microvolt = <3500000>;
					regulator-enable-ramp-delay = <680>;
					regulator-allowed-modes = <0 2>;
				};

				mt6369_vcn33_2: vcn33-2 {
					regulator-name = "mt6369_vcn33_2";
					regulator-min-microvolt = <1200000>;
					regulator-max-microvolt = <3500000>;
					regulator-enable-ramp-delay = <680>;
					regulator-allowed-modes = <0 2>;
				};

				mt6369_vant18: vant18 {
					regulator-name = "mt6369_vant18";
					regulator-min-microvolt = <600000>;
					regulator-max-microvolt = <2100000>;
					regulator-enable-ramp-delay = <680>;
					regulator-allowed-modes = <0 2>;
				};
			};
		};
	};
};

/ {
	consys@18000000 {
		compatible = "mediatek,mt6878-6631-consys";
		#thermal-sensor-cells = <0>;
		reg = <0 0x18000000 0 0x470>, <0 0x10001000 0 0xee4>,
		      <0 0x10005000 0 0xa7c>, <0 0x11ec0000 0 0xa04>,
		      <0 0x18001000 0 0x658>, <0 0x18003000 0 0x204>,
		      <0 0x1800e000 0 0x118>, <0 0x18011000 0 0x138>,
		      <0 0x18012000 0 0x98>, <0 0x18020000 0 0x4c>,
		      <0 0x18023000 0 0xe28>, <0 0x1803b000 0 0x18>,
		      <0 0x18040000 0 0x2c>, <0 0x18041000 0 0x140>,
		      <0 0x18042000 0 0x324>, <0 0x18046000 0 0x324>,
		      <0 0x1804b000 0 0x414>, <0 0x1804d000 0 0x41c>,
		      <0 0x1804f000 0 0x148>, <0 0x18053800 0 0x1000>,
		      <0 0x18060000 0 0xbf8>, <0 0x18070000 0 0x8004>,
		      <0 0x1c001000 0 0xfd0>, <0 0x1c00a000 0 0x51c>,
		      <0 0x1803c000 0 0x34>, <0 0x1803e000 0 0x34>;
		power-domains = <&conn_power 1>;
		mt6363_vcn13-supply = <&mt6363_vcn13>;
		mt6363_vrfio18-supply = <&mt6363_vrfio18>;
		mt6369_vcn33_1-supply = <&mt6369_vcn33_1>;
		mt6369_vcn33_2-supply = <&mt6369_vcn33_2>;
		mt6369_vant18-supply = <&mt6369_vant18>;
		emi-addr = <0 0x85e00000>;
		emi-size = <0xc00000>;
		ro-bt-emi-size = <0x2e0000>;
		ro-gps-emi-size = <0xa0000>;
		ro-wifi-emi-size = <0x300000>;
		ro-emi-size = <0x680000>;
		rw-emi-size = <0x480000>;
		emi-alignment = <0x100000>;
		emi-max-addr = <0x90000000>;
		adie-sku = <0 1>;
		status = "disabled";
	};

	wifi@18400000 {
		compatible = "mediatek,wifi";
		memory-region = <&{/reserved-memory/mblock-42-shared-dma-pool_wifi-reserve-memory_dma}>;
		remap-idx = <1>;
		reg = <0 0x18400000 0 0>, <0 0x18000000 0 0x700000>;
		interrupts = <0 0x1e4 4 0>, <0 0x2b4 4 0>;
		emi-addr = <0>;
		emi-size = <0x1400000>;
		emi-alignment = <0x1000000>;
		emi-max-addr = <0xc0000000>;
		status = "disabled";
	};
};

&{/soc@0/pinctrl} {
	fem_wlan7207h_wf0: wlan7207h-wf0-state {
		pins-cmd-dat {
			pinmux = <0x2101 0x2201 0x2301 0x2401>;
			mapping = <0x0 0x3 0x0 0x1 0x2 0x0 0x2 0x4 0x0>,
			          <0x3 0xb 0x0>;
		};
	};
	fem_wlan7207h_wf1: wlan7207h-wf1-state {
		pins-cmd-dat {
			pinmux = <0x2906 0x2a06 0x2b06>;
			mapping = <0x8 0x83 0x0 0x9 0x82 0x0 0xa 0x84 0x0>;
		};
	};
	fem_wlan7207c_wf0: wlan7207c-wf0-state {
		pins-cmd-dat {
			pinmux = <0x2501 0xbf03 0x2701 0x2801>;
			mapping = <0x4 0x4a 0x0 0x14 0x4b 0x0 0x6 0x4c 0x0>,
			          <0x7 0x41 0x0>;
		};
	};
	fem_wlan7207c_wf1: wlan7207c-wf1-state {
		pins-cmd-dat {
			pinmux = <0xbd03 0xc003 0xbe03 0x2601>;
			mapping = <0x12 0xca 0x0 0x15 0xcb 0x0 0x13 0xcc 0x0>,
			          <0x5 0xc1 0x0>;
		};
	};
	fem_qm42195_wf0: qm42195-wf0-state {
		pins-cmd-dat {
			pinmux = <0x2101 0x2201 0x2301 0x2401>;
			mapping = <0x0 0x3 0x0 0x1 0x2 0x0 0x2 0x4 0x0>,
			          <0x3 0xb 0x0>;
		};
	};
	fem_qm42195_wf1: qm42195-wf1-state {
		pins-cmd-dat {
			pinmux = <0x2906 0x2a06 0x2b06>;
			mapping = <0x8 0x83 0x0 0x9 0x82 0x0 0xa 0x84 0x0>;
		};
	};
	fem_qm45197_wf0: qm45197-wf0-state {
		pins-cmd-dat {
			pinmux = <0x2501 0xbf03 0x2701>;
			mapping = <0x4 0x4a 0x0 0x14 0x4b 0x0 0x6 0x4c 0x0>;
		};
	};
	fem_qm45197_wf1: qm45197-wf1-state {
		pins-cmd-dat {
			pinmux = <0xbd03 0xc003 0xbe03>;
			mapping = <0x12 0xca 0x0 0x15 0xcb 0x0 0x13 0xcc 0x0>;
		};
	};
	fem_sky85320_wf0: sky85320-wf0-state {
		pins-cmd-dat {
			pinmux = <0x2101 0x2201 0x2301 0x2401>;
			mapping = <0x0 0xc 0x0 0x1 0xd 0x0 0x2 0x2 0x0>,
			          <0x3 0xb 0x0>;
		};
	};
	fem_sky85720_wf0: sky85720-wf0-state {
		pins-cmd-dat {
			pinmux = <0x2501 0x2601>;
			mapping = <0x4 0x47 0x0 0x5 0x4b 0x0>;
		};
	};
	fem_mxd7751s_wf0: mxd7751s-wf0-state {
		pins-cmd-dat {
			pinmux = <0x2201 0x2301 0x2401 0x2501 0x2601 0x2701>;
			mapping = <0x1 0xb 0x0 0x2 0xd 0x0 0x3 0xc 0x0>,
			          <0x4 0x42 0x0 0x5 0x45 0x0 0x6 0x10 0x0>;
		};
	};
	fem_sky85732_wf0: sky85732-wf0-state {
		pins-cmd-dat {
			pinmux = <0x2501 0x2601>;
			mapping = <0x4 0x47 0x0 0x5 0x49 0x0>;
		};
	};
	fem_rtc7620_wf0: rtc7620-wf0-state {
		pins-cmd-dat {
			pinmux = <0x2101 0x2201 0x2301>;
			mapping = <0x0 0x6 0x0 0x1 0xb 0x0 0x2 0x1 0x0>;
		};
	};
};

/ {
	connfem {
		compatible = "mediatek,mt6878-connfem";
		status = "disabled";
		pinctrl-names = "wlan7207h-wlan7207c",
			        "qm42195-qm45197",
			        "sky85320-sky85720",
			        "mxd7751s-mxd7751s",
			        "nofem-sky85732",
			        "nofem-qm45197",
			        "rtc7620-nofem";
		pinctrl-0 = <&fem_wlan7207h_wf0 &fem_wlan7207h_wf1 &fem_wlan7207c_wf0 &fem_wlan7207c_wf1>;
		pinctrl-1 = <&fem_qm42195_wf0 &fem_qm42195_wf1 &fem_qm45197_wf0 &fem_qm45197_wf1>;
		pinctrl-2 = <&fem_sky85320_wf0 &fem_sky85720_wf0>;
		pinctrl-3 = <&fem_mxd7751s_wf0>;
		pinctrl-4 = <&fem_sky85732_wf0>;
		pinctrl-5 = <&fem_qm45197_wf0 &fem_qm45197_wf1>;
		pinctrl-6 = <&fem_rtc7620_wf0>;

		fem_nofem: nofem {
			vid = <0x0>;
			pid = <0x0>;
		};

		fem_wlan7207h: wlan7207h {
			vid = <0x2>;
			pid = <0x4>;
		};

		fem_wlan7207c: wlan7207c {
			vid = <0x2>;
			pid = <0x7>;
		};

		fem_qm42195: qm42195 {
			vid = <0x3>;
			pid = <0x1>;
		};

		fem_qm45197: qm45197 {
			vid = <0x3>;
			pid = <0x2>;
		};

		fem_sky85320: sky85320 {
			vid = <0x1>;
			pid = <0x1>;
		};

		fem_sky85720: sky85720 {
			vid = <0x1>;
			pid = <0x2>;
		};

		fem_mxd7751s: mxd7751s {
			vid = <0x4>;
			pid = <0x1>;
		};

		fem_sky85732: sky85732 {
			vid = <0x1>;
			pid = <0x3>;
		};

		fem_rtc7620: rtc7620 {
			vid = <0x6>;
			pid = <0x1>;
		};

		epa-elna-mtk {
			parts = <&fem_nofem &fem_nofem &fem_nofem &fem_nofem
				 &fem_nofem &fem_nofem &fem_mxd7751s &fem_mxd7751s
				 &fem_sky85320 &fem_sky85720 &fem_sky85320 &fem_sky85720
				 &fem_qm42195 &fem_qm45197 &fem_wlan7207h &fem_wlan7207c
				 &fem_nofem &fem_sky85732 &fem_nofem &fem_sky85732
				 &fem_nofem &fem_qm45197 &fem_rtc7620 &fem_nofem>;

			hwid {
				gpio = <&{/soc@0/pinctrl} 131 0>,
				       <&{/soc@0/pinctrl} 132 0>,
				       <&{/soc@0/pinctrl} 92 0>;
			};

			wifi {
				flags-3 {
				};
				flags-4 {
				};
				flags-5 {
				};
				flags-6 {
				};
				flags-7 {
				};
				flags-8 {
				};
				flags-9 {
				};
				flags-10 {
				};
				flags-11 {
				};
			};

			bt {
				flags-3 {
					bypass;
				};
				flags-4 {
					bypass;
				};
				flags-5 {
					bypass;
				};
				flags-6 {
					epa-elna;
				};
				flags-7 {
					epa-elna;
				};
				flags-8 {
					epa-elna;
				};
				flags-9 {
					bypass;
				};
				flags-10 {
					epa-elna;
				};
				flags-11 {
					epa-elna;
				};
			};
		};
	};
};
